# MKM14Z5 register map
File version: 1.6
Registers are 8-bit, read-write, reset 0x0 unless marked. A register's access mark holds for its fields unless they carry their own. Offsets are from the block's base; [hi:lo] are bit positions; {n}, {i} and the like mark numbered series.

## PMC — Power Management Controller
Base 0x4007D000; register names take the prefix PMC_
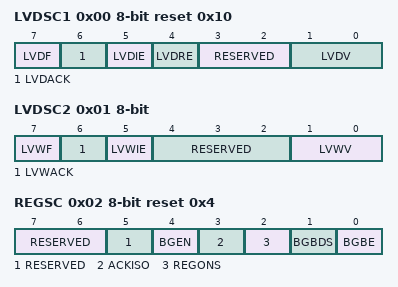
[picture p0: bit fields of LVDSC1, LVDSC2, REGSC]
0x00 LVDSC1 reset 0x10 — Low Voltage Detect Status And Control 1 register
  [7] LVDF ro — Low-Voltage Detect Flag
    0=Low-voltage event not detected; 1=Low-voltage event detected
  [6] LVDACK wo — Low-Voltage Detect Acknowledge
  [5] LVDIE — Low-Voltage Detect Interrupt Enable
    0=Hardware interrupt disabled (use polling); 1=Request a hardware interrupt when LVDF = 1
  [4] LVDRE — Low-Voltage Detect Reset Enable
    0=LVDF does not generate hardware resets; 1=Force an MCU reset when LVDF = 1
  [3:2] RESERVED ro
  [1:0] LVDV — Low-Voltage Detect Voltage Select
    0=Low trip point selected (V LVD = V LVDL ); 1=High trip point selected (V LVD = V LVDH )
0x01 LVDSC2 — Low Voltage Detect Status And Control 2 register
  [7] LVWF ro — Low-Voltage Warning Flag
    0=Low-voltage warning event not detected; 1=Low-voltage warning event detected
  [6] LVWACK wo — Low-Voltage Warning Acknowledge
  [5] LVWIE — Low-Voltage Warning Interrupt Enable
    0=Hardware interrupt disabled (use polling); 1=Request a hardware interrupt when LVWF = 1
  [4:2] RESERVED ro
  [1:0] LVWV — Low-Voltage Warning Voltage Select
    0=Low trip point selected (VLVW = VLVW1); 1=Mid 1 trip point selected (VLVW = VLVW2); 2=Mid 2 trip point selected (VLVW = VLVW3); 3=High trip point selected (VLVW = VLVW4)
0x02 REGSC reset 0x4 — Regulator Status And Control register
  [7:6] RESERVED ro
  [5] RESERVED
  [4] BGEN — Bandgap Enable In VLPx Operation
    0=Bandgap voltage reference is disabled in VLPx , and VLLSx modes; 1=Bandgap voltage reference is enabled in VLPx , and VLLSx modes
  [3] ACKISO — Acknowledge Isolation
    0=Peripherals and I/O pads are in normal run state; 1=Certain peripherals and I/O pads are in an isolated and latched state
  [2] REGONS ro — Regulator In Run Regulation Status
    0=Regulator is in stop regulation or in transition to/from it; 1=Regulator is in run regulation
  [1] BGBDS — Bandgap Buffer Drive Select
    0=Low drive; 1=High drive
  [0] BGBE — Bandgap Buffer Enable
    0=Bandgap buffer not enabled; 1=Bandgap buffer enabled

## SMC — System Mode Controller
Base 0x4007E000; register names take the prefix SMC_
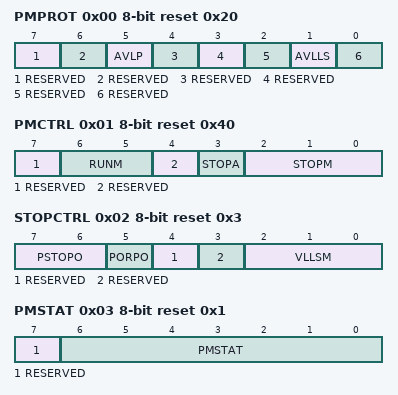
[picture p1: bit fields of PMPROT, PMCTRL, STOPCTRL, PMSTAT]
0x00 PMPROT reset 0x20 — Power Mode Protection register
  [7] RESERVED ro
  [6] RESERVED ro
  [5] AVLP — Allow Very-Low-Power Modes
    0=VLPR, VLPW and VLPS are not allowed; 1=VLPR, VLPW and VLPS are allowed
  [4] RESERVED ro
  [3] RESERVED ro
  [2] RESERVED ro
  [1] AVLLS — Allow Very-Low-Leakage Stop Mode
    0=Any VLLSx mode is not allowed; 1=Any VLLSx mode is allowed
  [0] RESERVED ro
0x01 PMCTRL reset 0x40 — Power Mode Control register
  [7] RESERVED ro
  [6:5] RUNM — Run Mode Control
    0=Normal Run mode (RUN); 2=Very-Low-Power Run mode (VLPR)
  [4] RESERVED ro
  [3] STOPA ro — Stop Aborted
    0=The previous stop mode entry was successsful; 1=The previous stop mode entry was aborted
  [2:0] STOPM — Stop Mode Control
    0=Normal Stop (STOP); 2=Very-Low-Power Stop (VLPS); 4=Very-Low-Leakage Stop (VLLSx); 6=Reseved
0x02 STOPCTRL reset 0x3 — Stop Control Register
  [7:6] PSTOPO — Partial Stop Option
    0=STOP - Normal Stop mode; 1=PSTOP1 - Partial Stop with both system and bus clocks disabled; 2=PSTOP2 - Partial Stop with system clock disabled and bus clock enabled
  [5] PORPO — POR Power Option
    0=POR detect circuit is enabled in VLLS0; 1=POR detect circuit is disabled in VLLS0
  [4] RESERVED ro
  [3] RESERVED ro
  [2:0] VLLSM — VLLS Mode Control
    {v}=VLLS{v} (v=0..3)
0x03 PMSTAT ro reset 0x1 — Power Mode Status register
  [7] RESERVED, [6:0] PMSTAT

## GPIOA — General Purpose Input/Output
Base 0x400FF000; register names take the prefix GPIOA_
0x00 PDOR — Port Data Output Register
  [7:0] PDO — Port Data Output
    0=Logic level 0 is driven on pin, provided pin is configured for general-purpose output; 1=Logic level 1 is driven on pin, provided pin is configured for general-purpose output
0x10 PDIR ro — Port Data Input Register
  [7:0] PDI — Port Data Input
    0=Pin logic level is logic 0, or is not configured for use by digital function; 1=Pin logic level is logic 1
0x14 PDDR — Port Data Direction Register
  [7:0] PDD — Port Data Direction
    0=Pin is configured as general-purpose input, for the GPIO function; 1=Pin is configured as general-purpose output, for the GPIO function
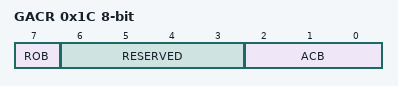
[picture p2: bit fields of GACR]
0x1C GACR — GPIO Attribute Checker Register
  [7] ROB — Read-Only Byte
    0=Writes to the ACB are allowed; 1=Writes to the ACB are ignored
  [6:3] RESERVED ro
  [2:0] ACB — Attribute Check Byte
    0=User nonsecure: Read + Write; User Secure: Read + Write; Privileged Secure: Read + Write; 1=User nonsecure: Read; User Secure: Read + Write; Privileged Secure: Read + Write; 2=User nonsecure: None; User Secure: Read + Write; Privileged Secure: Read + Write; 3=User nonsecure: Read; User Secure: Read; Privileged Secure: Read + Write; 4=User nonsecure: None; User Secure: Read; Privileged Secure: Read + Write; 5=User nonsecure: None; User Secure: None; Privileged Secure: Read + Write; 6=User nonsecure: None; User Secure: None; Privileged Secure: Read; 7=User nonsecure: None; User Secure: None; Privileged Secure: None

## GPIOB — General Purpose Input/Output
Base 0x400FF001; register names take the prefix GPIOB_
Registers as GPIOA.

## GPIOC — General Purpose Input/Output
Base 0x400FF002; register names take the prefix GPIOC_
Registers as GPIOA.

## GPIOD — General Purpose Input/Output
Base 0x400FF003; register names take the prefix GPIOD_
Registers as GPIOA.

## GPIOE — General Purpose Input/Output
Base 0x400FF040; register names take the prefix GPIOE_
Registers as GPIOA.

## GPIOF — General Purpose Input/Output
Base 0x400FF041; register names take the prefix GPIOF_
Registers as GPIOA.

## GPIOG — General Purpose Input/Output
Base 0x400FF042; register names take the prefix GPIOG_
Registers as GPIOA.

## GPIOH — General Purpose Input/Output
Base 0x400FF043; register names take the prefix GPIOH_
Registers as GPIOA.

## GPIOI — General Purpose Input/Output
Base 0x400FF080; register names take the prefix GPIOI_
Registers as GPIOA.
